# PIC32CX5109BZ31032 device description
Architecture: CORTEX-M4; Family: PIC32CX; Series: PIC32CXBZ31
Registers are 32-bit, read-write, reset 0x0 unless marked. A register's access mark holds for its fields unless they carry their own. Offsets are from the block's base; [hi:lo] are bit positions; {n}, {i} and the like mark numbered series.

## NVIC — Nested Vectored Interrupt Controller
Instances: NVIC 0xE000E100
{0x0+4i} ISER[{i}] (i=0..1) — Interrupt Set Enable Register
  [31:0] SETENA — Interrupt set enable bits
{0x80+4i} ICER[{i}] (i=0..1) — Interrupt Clear Enable Register
  [31:0] CLRENA — Interrupt clear-enable bits
{0x100+4i} ISPR[{i}] (i=0..1) — Interrupt Set Pending Register
  [31:0] SETPEND — Interrupt set-pending bits
{0x180+4i} ICPR[{i}] (i=0..1) — Interrupt Clear Pending Register
  [31:0] CLRPEND — Interrupt clear-pending bits
{0x200+4i} IABR[{i}] (i=0..1) — Interrupt Active Bit Register
  [31:0] ACTIVE — Interrupt active bits
{0x300+i} IP[{i}] (i=0..42) 8-bit — Interrupt Priority Register n
  [2:0] PRI0 — Priority of interrupt n
0xE00 STIR wo reset not defined — Software Trigger Interrupt Register
  [8:0] INTID — Interrupt ID to trigger

## ROT — Secure Root of Trust Macro
Instances: ROT 0x44002C00
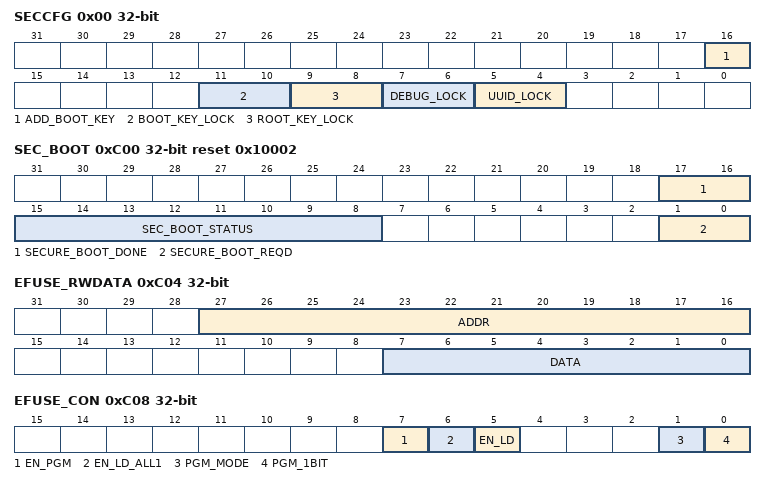
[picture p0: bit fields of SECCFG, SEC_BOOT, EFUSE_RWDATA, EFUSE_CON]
0x00 SECCFG — Secure Configuration HOLDING REGISTER1,2
  [16] ADD_BOOT_KEY — Additional boot Key bit
  [11:10] BOOT_KEY_LOCK — Lock bits for Secure Boot/OTA Key
    0=BOOT_KEY_NOT_LCK_0 (Secure boot key is not locked); 1=BOOT_KEY_LCK_1 (Secure boot key is locked and cannot be programmed); 2=BOOT_KEY_LCK_2 (Secure boot key is locked and cannot be programmed); 3=BOOT_KEY_LCK_3 (Secure boot key is locked and cannot be programmed)
  [9:8] ROOT_KEY_LOCK — Lock bits for storage root Key
    0=ROOT_KEY_NOT_LCK_0 (Storage root key is not locked); 1=ROOT_KEY_LCK_1 (Storage root key is locked and cannot be programmed); 2=ROOT_KEY_LCK_2 (Storage root key is locked and cannot be programmed); 3=ROOT_KEY_LCK_3 (Storage root key is locked and cannot be programmed)
  [7:6] DEBUG_LOCK — Lock bits for debug/programming
    0=DEBUG_NOT_LCK_0 (Debug is not locked); 1=DEBUG_LCK_1 (Debug is locked); 2=DEBUG_LCK_2 (Debug is locked); 3=DEBUG_LCK_3 (Debug is locked)
  [5:4] UUID_LOCK — Programming lock bits for Unique ID fuses
    0=UUID_NOT_LCK_0 (Unique ID is not locked); 1=UUID_LCK_1 (Unique ID is locked and cannot be programmed); 2=UUID_LCK_2 (Unique ID is locked and cannot be programmed); 3=UUID_LCK_3 (Unique ID is locked and cannot be programmed)
0xC00 SEC_BOOT reset 0x10002 — Secure Boot Register
  [17:16] SECURE_BOOT_DONE — Bits to indicate that secure boot is done
    0=SEC_BOOT_DONE_0 (S ecure boot is done); 1=SEC_BOOT_NOT_DONE_1 (S ecure boot is not done); 2=SEC_BOOT_NOT_DONE_2 (S ecure boot is not done); 3=SEC_BOOT_DONE_3 (S ecure boot is done)
  [15:8] SEC_BOOT_STATUS — Bits to indicate that secure boot status
  [1:0] SECURE_BOOT_REQD — Bits to indicate that secure boot is required on the next device reset.
    0=SEC_BOOT_REQD_0 (Secure boot code authentication is required); 1=SEC_BOOT_NOT_REQD_1 (Secure boot code authentication is NOT required); 2=SEC_BOOT_NOT_REQD_2 (Secure boot code authentication is NOT required); 3=SEC_BOOT_REQD_3 (Secure boot code authentication is required)
0xC04 EFUSE_RWDATA
  [27:16] ADDR — eFuse Program/Read Address
  [7:0] DATA — eFuse Program (Write) Data
0xC08 EFUSE_CON — Efuse Configuration Register2
  [7] EN_PGM — eFuse Programming Start bit
    0=EN_PGM_COMPLETED (EFuse Programming operation has completed); 1=EN_PGM_START (Start eFuse Programming operation)
  [6] EN_LD_ALL1 — eFuse Panel Read Start bit for loading into the holding registers
    0=ENLD_ALL1_READ_COMPLETED (EFuse Read operation has completed); 1=ENLD_ALL1_READ_START (Start eFuse Read operation for entire eFuse panel)
  [5] EN_LD — eFuse Word Read Start bit for loading the fuse byte pointed by ADDR field into the holding register
    0=ENLD_READ_COMPLETED (EFuse Read operation has completed); 1=ENLD_READ_START (Start eFuse Read operation for specified eFuse word as addressed in EFUSE_RWDATA register)
  [1] PGM_MODE — eFuse Programming Mode Enable bit
    0=PGM_MODE_DISABLED (EFuse Programming disabled); 1=PGM_MODE_ENABLED (EFuse Programming enabled)
  [0] PGM_1BIT — eFuse CTRL to program 1 bit at a time. Valid only when EN_PGM is set
    0=EFUSE_RW_15_0 (EFuse controller will program EFUSE_RWDATA.DATA[15:0] to the address in EFUSE_RWDATA.ADDR[11:3]); 1=EFUSE_RW_0 (EFuse controller will program EFUSE_RWDATA.DATA[0] to the address in EFUSE_RWDATA.ADDR[11:0])
